VERSION ""

NS_ :

BS_:

BU_: Debug_Laptop
VAL_TABLE_ Event 6 "Braketest" 5 "DV" 4 "Endurance" 3 "AutoX" 2 "Skidpad" 1 "Accel" 0 "Testing" ;
VAL_TABLE_ TS_State 3 "TS_Error" 2 "TS_R2D" 1 "TS_Active" 0 "TS_Off" ;

BO_ 3221225472 VECTOR__INDEPENDENT_SIG_MSG: 0 Vector__XXX
 SG_ CCP_Session_ID : 0|8@1+ (1,0) [0|255] "" Vector__XXX
 SG_ CCP_Session_ID : 0|8@1+ (1,0) [0|255] "" Vector__XXX
 SG_ CCP_Session_ID : 0|8@1+ (1,0) [0|255] "" Vector__XXX
 SG_ CCP_Session_ID : 0|8@1+ (1,0) [0|255] "" Vector__XXX
 SG_ CCP_Session_ID : 0|8@1+ (1,0) [0|255] "" Vector__XXX

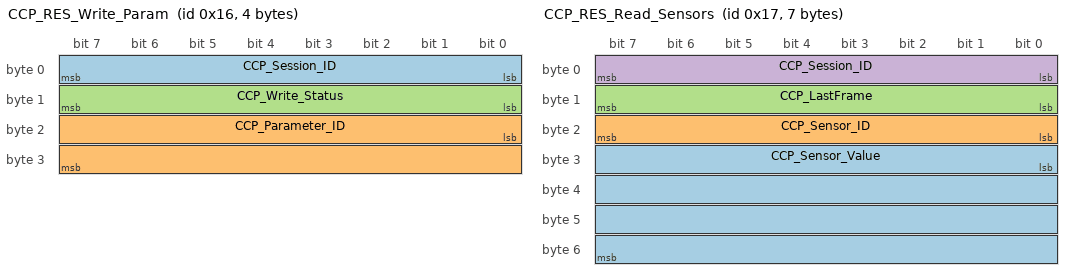
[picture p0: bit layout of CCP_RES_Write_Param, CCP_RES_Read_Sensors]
BO_ 22 CCP_RES_Write_Param: 4 Vector__XXX
 SG_ CCP_Session_ID : 0|8@1+ (1,0) [0|255] "" Vector__XXX
 SG_ CCP_Parameter_ID : 16|16@1+ (1,0) [0|65535] "" Vector__XXX
 SG_ CCP_Write_Status : 8|8@1+ (1,0) [0|255] "" Vector__XXX

BO_ 23 CCP_RES_Read_Sensors: 7 Vector__XXX
 SG_ CCP_Sensor_Value : 24|32@1+ (1,0) [0|4294967295] "" Vector__XXX
 SG_ CCP_Sensor_ID : 16|8@1+ (1,0) [0|255] "" Vector__XXX
 SG_ CCP_LastFrame : 8|8@1+ (1,0) [0|1] "" Vector__XXX
 SG_ CCP_Session_ID : 0|8@1+ (1,0) [0|255] "" Vector__XXX

BO_ 7 CCP_CMD_Read_Sensors: 1 Vector__XXX
 SG_ CCP_Session_ID : 0|8@1+ (1,0) [0|255] "" Vector__XXX

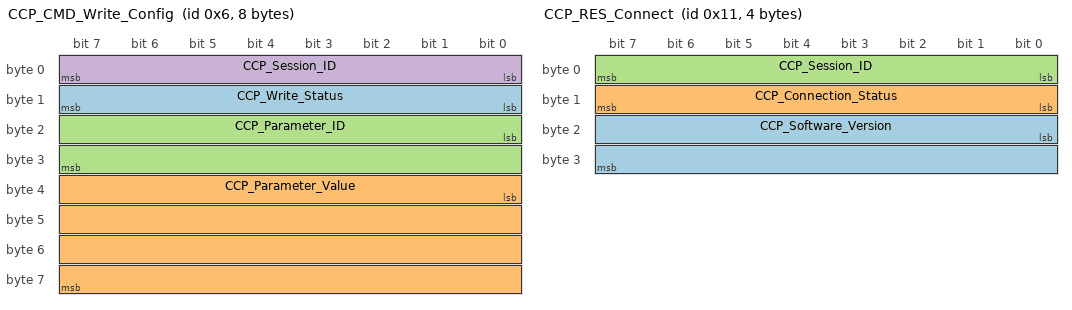
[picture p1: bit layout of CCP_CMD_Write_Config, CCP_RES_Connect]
BO_ 6 CCP_CMD_Write_Config: 8 Debug_Laptop
 SG_ CCP_Write_Status : 8|8@1+ (1,0) [0|255] "" Vector__XXX
 SG_ CCP_Parameter_Value : 32|32@1+ (1,0) [0|4294967295] "" Vector__XXX
 SG_ CCP_Parameter_ID : 16|16@1+ (1,0) [0|65535] "" Vector__XXX
 SG_ CCP_Session_ID : 0|8@1+ (1,0) [0|255] "" Vector__XXX

BO_ 19 CCP_RES_Reboot: 1 Vector__XXX
 SG_ CCP_Session_ID : 0|8@1+ (1,0) [0|255] "" Vector__XXX

BO_ 18 CCP_RES_Quit: 1 Vector__XXX
 SG_ CCP_Session_ID : 0|8@1+ (1,0) [0|255] "" Vector__XXX

BO_ 1 CCP_CMD_Connect: 1 Vector__XXX
 SG_ CCP_ECU_ID : 0|8@1+ (1,0) [0|255] "" Vector__XXX

BO_ 2 CCP_CMD_Quit: 1 Debug_Laptop
 SG_ CCP_Session_ID : 0|8@1+ (1,0) [0|255] "" Vector__XXX

BO_ 17 CCP_RES_Connect: 4 Vector__XXX
 SG_ CCP_Software_Version : 16|16@1+ (1,0) [0|65535] "" Vector__XXX
 SG_ CCP_Connection_Status : 8|8@1+ (1,0) [0|255] "" Vector__XXX
 SG_ CCP_Session_ID : 0|8@1+ (1,0) [0|255] "" Vector__XXX

BO_ 3 CCP_CMD_Reboot: 1 Debug_Laptop
 SG_ CCP_Session_ID : 0|8@1+ (1,0) [0|255] "" Vector__XXX

CM_ BO_ 3221225472 "This is a message for not used signals, created by Vector CANdb++ DBC OLE DB Provider.";
BA_DEF_ SG_  "GenSigSendType" ENUM  "Cyclic","OnWrite","OnWriteWithRepetition","OnChange","OnChangeWithRepetition","IfActive","IfActiveWithRepetition","NoSigSendType";
BA_DEF_ BO_  "GenMsgSendType" ENUM  "Cyclic","not_used","not_used","not_used","not_used","Cyclic","not_used","IfActive","NoMsgSendType";
BA_DEF_  "Bus Speed" STRING ;
BA_DEF_  "DBName" STRING ;
BA_DEF_  "BusType" STRING ;
BA_DEF_DEF_  "GenSigSendType" "Cyclic";
BA_DEF_DEF_  "GenMsgSendType" "NoMsgSendType";
BA_DEF_DEF_  "Bus Speed" "1000k";
BA_DEF_DEF_  "DBName" "";
BA_DEF_DEF_  "BusType" "CAN";
BA_ "DBName" "CCP";
